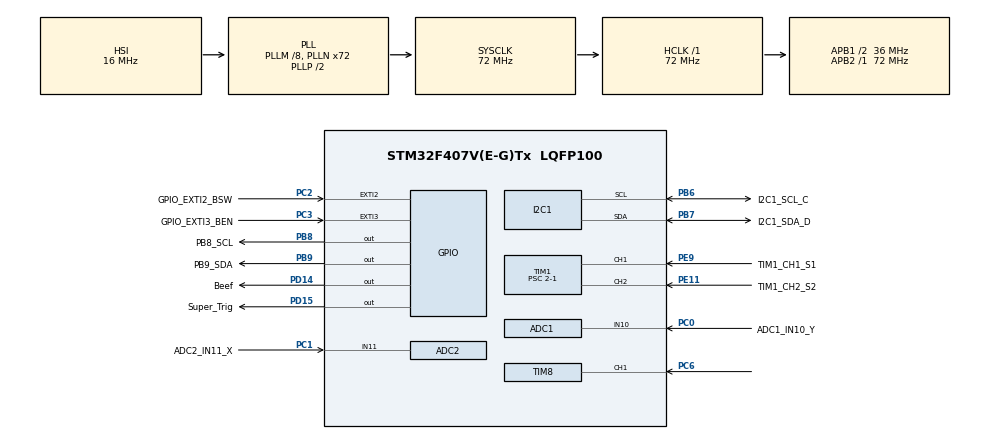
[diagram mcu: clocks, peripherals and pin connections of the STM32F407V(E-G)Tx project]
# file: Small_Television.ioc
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ADC1.Channel-6\#ChannelRegularConversion=ADC_CHANNEL_10
ADC1.ContinuousConvMode=ENABLE
ADC1.InjNumberOfConversion=0
ADC1.NbrOfConversion=1
ADC1.NbrOfConversionFlag=1
ADC1.Rank-6\#ChannelRegularConversion=1
ADC1.SamplingTime-6\#ChannelRegularConversion=ADC_SAMPLETIME_28CYCLES
ADC1.ScanConvMode=ENABLE
ADC1.master=1
ADC2.Channel-0\#ChannelRegularConversion=ADC_CHANNEL_11
ADC2.ContinuousConvMode=ENABLE
ADC2.NbrOfConversionFlag=1
ADC2.Rank-0\#ChannelRegularConversion=1
ADC2.SamplingTime-0\#ChannelRegularConversion=ADC_SAMPLETIME_28CYCLES
ADC2.ScanConvMode=ENABLE
Dma.ADC1.0.Direction=DMA_PERIPH_TO_MEMORY
Dma.ADC1.0.FIFOMode=DMA_FIFOMODE_DISABLE
Dma.ADC1.0.Instance=DMA2_Stream0
Dma.ADC1.0.MemDataAlignment=DMA_MDATAALIGN_HALFWORD
Dma.ADC1.0.MemInc=DMA_MINC_ENABLE
Dma.ADC1.0.Mode=DMA_CIRCULAR
Dma.ADC1.0.PeriphDataAlignment=DMA_PDATAALIGN_HALFWORD
Dma.ADC1.0.PeriphInc=DMA_PINC_DISABLE
Dma.ADC1.0.Priority=DMA_PRIORITY_LOW
Dma.ADC2.1.Direction=DMA_PERIPH_TO_MEMORY
Dma.ADC2.1.FIFOMode=DMA_FIFOMODE_DISABLE
Dma.ADC2.1.Instance=DMA2_Stream2
Dma.ADC2.1.MemDataAlignment=DMA_MDATAALIGN_HALFWORD
Dma.ADC2.1.MemInc=DMA_MINC_ENABLE
Dma.ADC2.1.Mode=DMA_CIRCULAR
Dma.ADC2.1.PeriphDataAlignment=DMA_PDATAALIGN_HALFWORD
Dma.ADC2.1.PeriphInc=DMA_PINC_DISABLE
Dma.ADC2.1.Priority=DMA_PRIORITY_LOW
Dma.Request0=ADC1
Dma.Request1=ADC2
Mcu.Family=STM32F4
Mcu.Name=STM32F407V(E-G)Tx
Mcu.Package=LQFP100
NVIC.DMA2_Stream0_IRQn=true\:0\:0\:false\:false\:true\:false\:true\:true
NVIC.DMA2_Stream2_IRQn=true\:0\:0\:false\:false\:true\:false\:true\:true
NVIC.EXTI2_IRQn=true\:0\:0\:false\:false\:true\:true\:true\:true
NVIC.EXTI3_IRQn=true\:0\:0\:false\:false\:true\:true\:true\:true
NVIC.PriorityGroup=NVIC_PRIORITYGROUP_4
NVIC.TIM2_IRQn=true\:0\:0\:false\:false\:true\:true\:true\:true
NVIC.TIM8_CC_IRQn=true\:0\:0\:false\:false\:true\:true\:true\:true
PA13.Mode=Serial_Wire
PA13.Signal=SYS_JTMS-SWDIO
PA14.Mode=Serial_Wire
PA14.Signal=SYS_JTCK-SWCLK
PB6.GPIO_Label=I2C1_SCL_C
PB6.Mode=I2C
PB6.Signal=I2C1_SCL
PB7.GPIO_Label=I2C1_SDA_D
PB7.Mode=I2C
PB7.Signal=I2C1_SDA
PB8.GPIO_Label=PB8_SCL
PB8.Signal=GPIO_Output
PB9.GPIO_Label=PB9_SDA
PB9.Signal=GPIO_Output
PC0.GPIO_Label=ADC1_IN10_Y
PC0.Signal=ADCx_IN10
PC1.GPIO_Label=ADC2_IN11_X
PC1.Signal=ADCx_IN11
PC2.GPIO_Label=GPIO_EXTI2_BSW
PC2.GPIO_ModeDefaultEXTI=GPIO_MODE_IT_RISING
PC2.GPIO_PuPd=GPIO_PULLUP
PC2.Signal=GPXTI2
PC3.GPIO_Label=GPIO_EXTI3_BEN
PC3.GPIO_PuPd=GPIO_PULLUP
PC3.Signal=GPXTI3
PC6.Signal=S_TIM8_CH1
PD14.GPIO_Label=Beef
PD14.Signal=GPIO_Output
PD15.GPIO_Label=Super_Trig
PD15.Signal=GPIO_Output
PE11.GPIO_Label=TIM1_CH2_S2
PE11.Signal=S_TIM1_CH2
PE9.GPIO_Label=TIM1_CH1_S1
PE9.Signal=S_TIM1_CH1
PH0-OSC_IN.Mode=HSE-External-Oscillator
PH0-OSC_IN.Signal=RCC_OSC_IN
PH1-OSC_OUT.Mode=HSE-External-Oscillator
PH1-OSC_OUT.Signal=RCC_OSC_OUT
ProjectManager.HeapSize=0x200
ProjectManager.StackSize=0x400
ProjectManager.TargetToolchain=SW4STM32
RCC.48MHZClocksFreq_Value=36000000
RCC.AHBFreq_Value=72000000
RCC.APB1CLKDivider=RCC_HCLK_DIV2
RCC.APB1Freq_Value=36000000
RCC.APB1TimFreq_Value=72000000
RCC.APB2Freq_Value=72000000
RCC.APB2TimFreq_Value=72000000
RCC.CortexFreq_Value=72000000
RCC.HCLKFreq_Value=72000000
RCC.HSE_VALUE=25000000
RCC.HSI_VALUE=16000000
RCC.LSE_VALUE=32768
RCC.PLLM=8
RCC.PLLN=72
RCC.SYSCLKFreq_VALUE=72000000
RCC.SYSCLKSource=RCC_SYSCLKSOURCE_PLLCLK
RCC.VCOOutputFreq_Value=144000000
SH.ADCx_IN10.0=ADC1_IN10,IN10
SH.ADCx_IN11.0=ADC2_IN11,IN11
SH.S_TIM1_CH1.0=TIM1_CH1,Encoder_Interface
SH.S_TIM1_CH2.0=TIM1_CH2,Encoder_Interface
SH.S_TIM8_CH1.0=TIM8_CH1,Input_Capture1_from_TI1
TIM1.IC1Filter=15
TIM1.IC2Filter=15
TIM1.IC2Polarity=TIM_ICPOLARITY_FALLING
TIM1.Prescaler=2-1
TIM2.Period=10000-1
TIM2.Prescaler=7200-1
TIM5.Prescaler=72-1
TIM8.Channel-Input_Capture1_from_TI1=TIM_CHANNEL_1
TIM8.Channel-Input_Capture2_from_TI1_63=TIM_CHANNEL_2
TIM8.ICPolarity_CH2=TIM_INPUTCHANNELPOLARITY_FALLING
TIM8.Prescaler=72-1
VP_TIM2_VS_ClockSourceINT.Mode=Internal
VP_TIM5_VS_ClockSourceINT.Mode=Internal
VP_TIM8_VS_ClockSourceINT.Mode=Internal
VP_TIM8_VS_indirect_ch1.Mode=Input_Capture2_from_TI1_63
board=custom

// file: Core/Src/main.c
/* USER CODE BEGIN Header */
/**
  ******************************************************************************
  * @file           : main.c
  * @brief          : Main program body
  ******************************************************************************
  * @attention
  *
  * Copyright (c) 2024 STMicroelectronics.
  * All rights reserved.
  *
  * This software is licensed under terms that can be found in the LICENSE file
  * in the root directory of this software component.
  * If no LICENSE file comes with this software, it is provided AS-IS.
  *
  ******************************************************************************
  */
/* USER CODE END Header */
#include "main.h"
#include "adc.h"
#include "dma.h"
#include "i2c.h"
#include "tim.h"
#include "gpio.h"

/* USER CODE BEGIN Includes */
#include "Cpp_Hand.h"
/* USER CODE END Includes */

void SystemClock_Config(void);

int main(void)
{

  /* MCU Configuration--------------------------------------------------------*/

  /* Reset of all peripherals, Initializes the Flash interface and the Systick. */
  HAL_Init();

  /* Configure the system clock */
  SystemClock_Config();

  /* Initialize all configured peripherals */
  MX_GPIO_Init();
  MX_ADC1_Init();
  MX_DMA_Init();
  MX_I2C1_Init();
  MX_TIM5_Init();
  MX_ADC2_Init();
  MX_TIM1_Init();
  MX_TIM8_Init();
  MX_TIM2_Init();
  /* USER CODE BEGIN 2 */
    Start_Hand();
  /* USER CODE END 2 */

  /* Infinite loop */
  /* USER CODE BEGIN WHILE */

  Loop_Hand();
    /* USER CODE END WHILE */

}

void SystemClock_Config(void)
{
  RCC_OscInitTypeDef RCC_OscInitStruct = {0};
  RCC_ClkInitTypeDef RCC_ClkInitStruct = {0};

  /** Configure the main internal regulator output voltage
  */
  __HAL_RCC_PWR_CLK_ENABLE();
  __HAL_PWR_VOLTAGESCALING_CONFIG(PWR_REGULATOR_VOLTAGE_SCALE1);

  /** Initializes the RCC Oscillators according to the specified parameters
  * in the RCC_OscInitTypeDef structure.
  */
  RCC_OscInitStruct.OscillatorType = RCC_OSCILLATORTYPE_HSI;
  RCC_OscInitStruct.HSIState = RCC_HSI_ON;
  RCC_OscInitStruct.HSICalibrationValue = RCC_HSICALIBRATION_DEFAULT;
  RCC_OscInitStruct.PLL.PLLState = RCC_PLL_ON;
  RCC_OscInitStruct.PLL.PLLSource = RCC_PLLSOURCE_HSI;
  RCC_OscInitStruct.PLL.PLLM = 8;
  RCC_OscInitStruct.PLL.PLLN = 72;
  RCC_OscInitStruct.PLL.PLLP = RCC_PLLP_DIV2;
  RCC_OscInitStruct.PLL.PLLQ = 4;
  if (HAL_RCC_OscConfig(&RCC_OscInitStruct) != HAL_OK)
  {
    Error_Handler();
  }

  /** Initializes the CPU, AHB and APB buses clocks
  */
  RCC_ClkInitStruct.ClockType = RCC_CLOCKTYPE_HCLK|RCC_CLOCKTYPE_SYSCLK
                              |RCC_CLOCKTYPE_PCLK1|RCC_CLOCKTYPE_PCLK2;
  RCC_ClkInitStruct.SYSCLKSource = RCC_SYSCLKSOURCE_PLLCLK;
  RCC_ClkInitStruct.AHBCLKDivider = RCC_SYSCLK_DIV1;
  RCC_ClkInitStruct.APB1CLKDivider = RCC_HCLK_DIV2;
  RCC_ClkInitStruct.APB2CLKDivider = RCC_HCLK_DIV1;

  if (HAL_RCC_ClockConfig(&RCC_ClkInitStruct, FLASH_LATENCY_2) != HAL_OK)
  {
    Error_Handler();
  }
}

void Error_Handler(void)
{
  __disable_irq();
  while (1)
  {
  }
}
